# TLSR8258 register map
File version: 0.1
Auto-generated SVD for Telink TLSR8258
Registers are 8-bit, access not given, no defined reset value unless marked. A register's access mark holds for its fields unless they carry their own. Offsets are from the block's base; lines under a group give offsets from that group; [hi:lo] are bit positions; {n}, {i} and the like mark numbered series; 'fields as' and 'values as' point back to an identical list; <NAME> marks a mode.

## Memory map
0x00800000 I2C — Auto-generated from section 'i2c'
0x00800008 SPI — Auto-generated from section 'spi'
0x0080000C MSPI — Auto-generated from section 'mspi'
0x00800060 RESET — Auto-generated from section 'reset'
0x0080007B N_7816 — Auto-generated from section '7816'
0x00800090 UART — Auto-generated from section 'uart'
0x008000B0 SWIRE — Auto-generated from section 'swire'
0x008000B8 ANALOG_CONTROL — Auto-generated from section 'analog control'
0x008000E0 I2C_ADDRESS_MAP — Auto-generated from section 'i2c address map'
0x00800100 USB — Auto-generated from section 'usb'
0x00800540 AES — Auto-generated from section 'aes'
0x00800560 AUDIO — Auto-generated from section 'audio'
0x00800580 GPIO — Auto-generated from section 'gpio'
0x00800620 TIMER — Auto-generated from section 'timer'
0x00800640 IRQ — Auto-generated from section 'irq'
0x00800740 SYSTEM_TIMER — Auto-generated from section 'system timer'
0x00800780 PWM — Auto-generated from section 'pwm'
0x00800800 FIFO — Auto-generated from section 'fifo'
0x00800B00 DFIFO — Auto-generated from section 'dfifo'
0x00800C00 DMA — Auto-generated from section 'dma'
0x00800F02 LINKLAYER — Auto-generated from section 'linklayer'

## I2C — Auto-generated from section 'i2c'
Base 0x00800000
0x00 I2C_SET 32-bit — Auto-generated from i2c_set; aliases: I2C_SPEED
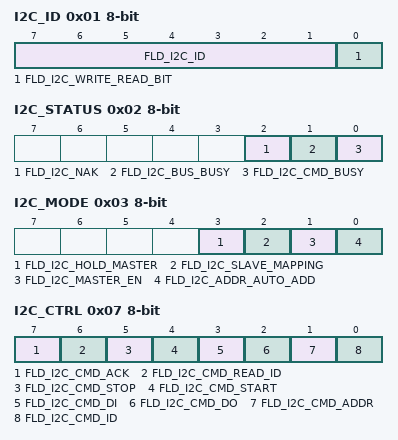
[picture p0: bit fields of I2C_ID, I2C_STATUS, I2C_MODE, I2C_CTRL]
0x01 I2C_ID — Auto-generated from i2c_id
  [7:1] FLD_I2C_ID, [0] FLD_I2C_WRITE_READ_BIT
0x02 I2C_STATUS — Auto-generated from i2c_status
  [2] FLD_I2C_NAK, [1] FLD_I2C_BUS_BUSY, [0] FLD_I2C_CMD_BUSY
0x03 I2C_MODE — Auto-generated from i2c_mode
  [3] FLD_I2C_HOLD_MASTER, [2] FLD_I2C_SLAVE_MAPPING, [1] FLD_I2C_MASTER_EN, [0] FLD_I2C_ADDR_AUTO_ADD
0x04 I2C_ADR_DAT 32-bit — Auto-generated from i2c_adr_dat; aliases: I2C_ADR, I2C_DAT_CTRL
0x05 I2C_DO — Auto-generated from i2c_do
0x06 I2C_DI_CTRL 16-bit — Auto-generated from i2c_di_ctrl; aliases: I2C_DI
0x07 I2C_CTRL — Auto-generated from i2c_ctrl
  [7] FLD_I2C_CMD_ACK, [6] FLD_I2C_CMD_READ_ID, [5] FLD_I2C_CMD_STOP, [4] FLD_I2C_CMD_START, [3] FLD_I2C_CMD_DI, [2] FLD_I2C_CMD_DO, [1] FLD_I2C_CMD_ADDR, [0] FLD_I2C_CMD_ID

## SPI — Auto-generated from section 'spi'
Base 0x00800008
0x00 SPI_DATA — Auto-generated from spi_data
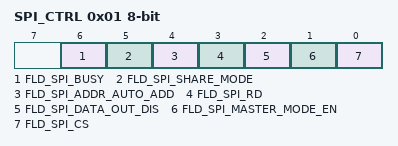
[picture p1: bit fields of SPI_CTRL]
0x01 SPI_CTRL — Auto-generated from spi_ctrl
  [6] FLD_SPI_BUSY, [5] FLD_SPI_SHARE_MODE, [4] FLD_SPI_ADDR_AUTO_ADD, [3] FLD_SPI_RD, [2] FLD_SPI_DATA_OUT_DIS, [1] FLD_SPI_MASTER_MODE_EN, [0] FLD_SPI_CS
0x02 SPI_SP — Auto-generated from spi_sp
  [7] FLD_SPI_ENABLE, [6:0] FLD_MSPI_CLK, [1:0] FLD_SPI_MODE_WORK_MODE

## MSPI — Auto-generated from section 'mspi'
Base 0x0080000C
0x00 MSPI_DATA — Auto-generated from mspi_data
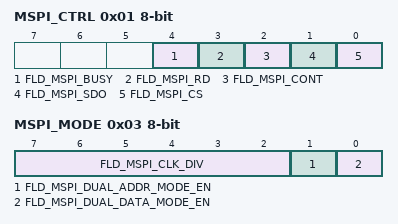
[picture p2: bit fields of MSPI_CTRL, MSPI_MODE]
0x01 MSPI_CTRL — Auto-generated from mspi_ctrl
  [4] FLD_MSPI_BUSY, [3] FLD_MSPI_RD, [2] FLD_MSPI_CONT, [1] FLD_MSPI_SDO, [0] FLD_MSPI_CS
0x03 MSPI_MODE — Auto-generated from mspi_mode
  [7:2] FLD_MSPI_CLK_DIV, [1] FLD_MSPI_DUAL_ADDR_MODE_EN, [0] FLD_MSPI_DUAL_DATA_MODE_EN

## RESET — Auto-generated from section 'reset'
Base 0x00800060
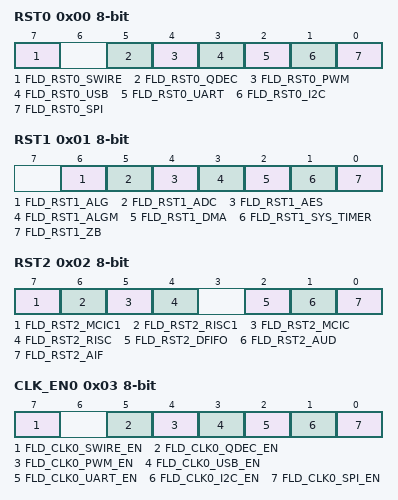
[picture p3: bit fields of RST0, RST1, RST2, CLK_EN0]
0x00 RST0 — Auto-generated from rst0
  [7] FLD_RST0_SWIRE, [5] FLD_RST0_QDEC, [4] FLD_RST0_PWM, [3] FLD_RST0_USB, [2] FLD_RST0_UART, [1] FLD_RST0_I2C, [0] FLD_RST0_SPI
0x01 RST1 — Auto-generated from rst1
  [6] FLD_RST1_ALG, [5] FLD_RST1_ADC, [4] FLD_RST1_AES, [3] FLD_RST1_ALGM, [2] FLD_RST1_DMA, [1] FLD_RST1_SYS_TIMER, [0] FLD_RST1_ZB
0x02 RST2 — Auto-generated from rst2
  [7] FLD_RST2_MCIC1, [6] FLD_RST2_RISC1, [5] FLD_RST2_MCIC, [4] FLD_RST2_RISC, [2] FLD_RST2_DFIFO, [1] FLD_RST2_AUD, [0] FLD_RST2_AIF
0x03 CLK_EN0 — Auto-generated from clk_en0
  [7] FLD_CLK0_SWIRE_EN, [5] FLD_CLK0_QDEC_EN, [4] FLD_CLK0_PWM_EN, [3] FLD_CLK0_USB_EN, [2] FLD_CLK0_UART_EN, [1] FLD_CLK0_I2C_EN, [0] FLD_CLK0_SPI_EN
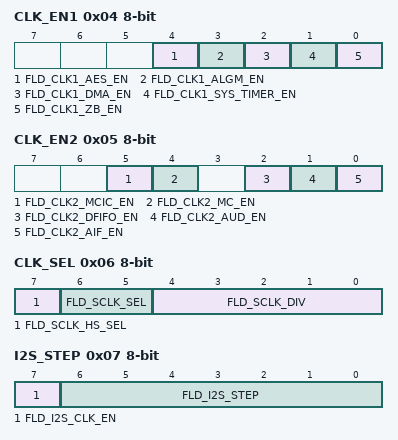
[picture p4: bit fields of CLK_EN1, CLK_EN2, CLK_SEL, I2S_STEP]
0x04 CLK_EN1 — Auto-generated from clk_en1
  [4] FLD_CLK1_AES_EN, [3] FLD_CLK1_ALGM_EN, [2] FLD_CLK1_DMA_EN, [1] FLD_CLK1_SYS_TIMER_EN, [0] FLD_CLK1_ZB_EN
0x05 CLK_EN2 — Auto-generated from clk_en2
  [5] FLD_CLK2_MCIC_EN, [4] FLD_CLK2_MC_EN, [2] FLD_CLK2_DFIFO_EN, [1] FLD_CLK2_AUD_EN, [0] FLD_CLK2_AIF_EN
0x06 CLK_SEL — Auto-generated from clk_sel
  [7] FLD_SCLK_HS_SEL, [6:5] FLD_SCLK_SEL, [4:0] FLD_SCLK_DIV
0x07 I2S_STEP — Auto-generated from i2s_step
  [7] FLD_I2S_CLK_EN, [6:0] FLD_I2S_STEP
0x08 I2S_MOD — Auto-generated from i2s_mod
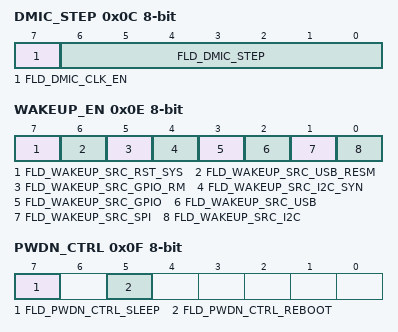
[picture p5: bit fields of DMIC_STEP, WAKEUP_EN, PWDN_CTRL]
0x0C DMIC_STEP — Auto-generated from dmic_step
  [7] FLD_DMIC_CLK_EN, [6:0] FLD_DMIC_STEP
0x0D DMIC_MOD — Auto-generated from dmic_mod
0x0E WAKEUP_EN — Auto-generated from wakeup_en
  [7] FLD_WAKEUP_SRC_RST_SYS, [6] FLD_WAKEUP_SRC_USB_RESM, [5] FLD_WAKEUP_SRC_GPIO_RM, [4] FLD_WAKEUP_SRC_I2C_SYN, [3] FLD_WAKEUP_SRC_GPIO, [2] FLD_WAKEUP_SRC_USB, [1] FLD_WAKEUP_SRC_SPI, [0] FLD_WAKEUP_SRC_I2C
0x0F PWDN_CTRL — Auto-generated from pwdn_ctrl
  [7] FLD_PWDN_CTRL_SLEEP, [5] FLD_PWDN_CTRL_REBOOT
0x18 MCU_WAKEUP_MASK 32-bit — Auto-generated from mcu_wakeup_mask
